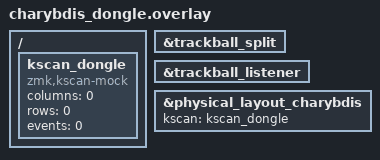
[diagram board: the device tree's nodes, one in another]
#include "charybdis.dtsi"



&trackball_split {
  status = "okay";
};

/* enable the listener on central */
&trackball_listener {
  status = "okay";
};


/ {
    kscan_dongle: kscan_dongle {
        compatible = "zmk,kscan-mock";
        columns = <0>;
        rows = <0>;
        events = <0>;
    };
};

&physical_layout_charybdis {
    kscan = <&kscan_dongle>;
};

